# CC13x0 register map
File version: 2.0
CPU: CM3 r2p1, little endian, no MPU, no FPU, 0x3 interrupt priority bits, 0x0 interrupts
Registers are 32-bit, read-write, reset 0x0 unless marked. A register's access mark holds for its fields unless they carry their own. Offsets are from the block's base; [hi:lo] are bit positions; {n}, {i} and the like mark numbered series.

## AON_BATMON — Always On (AON) Battery And Temperature MONitor (BATMON) residing in the AON domain Note: This module only supports 32 bit Read/Write access from MCU.
Base 0x40095000
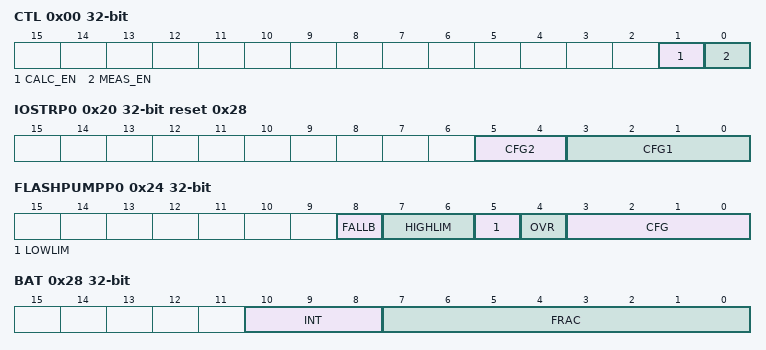
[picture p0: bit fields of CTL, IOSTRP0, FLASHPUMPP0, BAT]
0x00 CTL — Internal. Only to be used through TI provided API.
  [1] CALC_EN, [0] MEAS_EN
0x04 MEASCFG — Internal. Only to be used through TI provided API.
  [1:0] PER
0x0C TEMPP0 — Internal. Only to be used through TI provided API.
  [7:0] CFG
0x10 TEMPP1 — Internal. Only to be used through TI provided API.
  [5:0] CFG
0x14 TEMPP2 — Internal. Only to be used through TI provided API.
  [4:0] CFG
0x18 BATMONP0 — Internal. Only to be used through TI provided API.
  [5:0] CFG
0x1C BATMONP1 — Internal. Only to be used through TI provided API.
  [5:0] CFG
0x20 IOSTRP0 reset 0x28 — Internal. Only to be used through TI provided API.
  [5:4] CFG2, [3:0] CFG1
0x24 FLASHPUMPP0 — Internal. Only to be used through TI provided API.
  [8] FALLB, [7:6] HIGHLIM, [5] LOWLIM, [4] OVR, [3:0] CFG
0x28 BAT ro — Last Measured Battery Voltage This register may be read while BATUPD.STAT = 1
  [10:8] INT, [7:0] FRAC
0x2C BATUPD — Battery Update Indicates BAT Updates
  [0] STAT write-1-clears
0x30 TEMP ro — Temperature Last Measured Temperature in Degrees Celsius This register may be read while TEMPUPD.STAT = 1.
  [16:8] INT
0x34 TEMPUPD — Temperature Update Indicates TEMP Updates
  [0] STAT write-1-clears

## AON_EVENT — This module configures the event fabric located in the AON domain. Note: This module is only supporting 32 bit ReadWrite access from MCU
Base 0x40093000
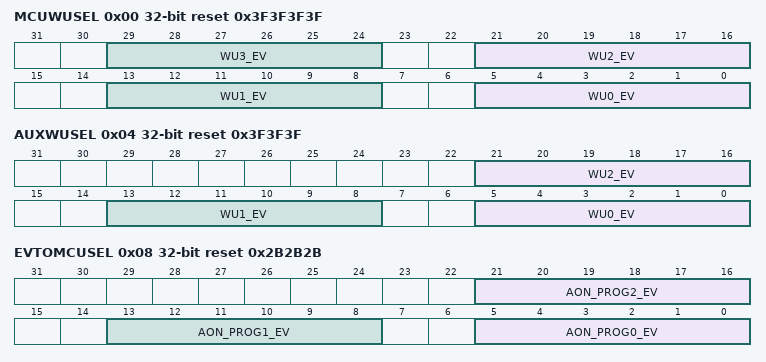
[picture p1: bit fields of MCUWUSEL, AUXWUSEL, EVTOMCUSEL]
0x00 MCUWUSEL reset 0x3F3F3F3F — Wake-up Selector For MCU This register contains pointers to 4 events which are routed to AON_WUC as wakeup sources for MCU. AON_WUC will start a wakeup sequence for the MCU domain when either of the 4 selected events are asserted. A wakeup sequence will guarantee that the MCU power switches are turned on, LDO resources are available and SCLK_HF is available and selected as clock source for MCU. Note: It is recommended ( or required when AON_WUC:MCUCLK.PWR_DWN_SRC=NONE) to also setup a wakeup event here before MCU is requesting powerdown. ( PRCM requests uLDO, see conditions in PRCM:VDCTL.ULDO ) as it will speed up the wakeup procedure.
  [8n+5:8n] WU{n}_EV (n=0..3)
0x04 AUXWUSEL reset 0x3F3F3F — Wake-up Selector For AUX This register contains pointers to 3 events which are routed to AON_WUC as wakeup sources for AUX. AON_WUC will start a wakeup sequence for the AUX domain when either of the 3 selected events are asserted. A wakeup sequence will guarantee that the AUX power switches are turned on, LDO resources are available and SCLK_HF is available and selected as clock source for AUX. Note: It is recommended ( or required when AON_WUC:AUXCLK.PWR_DWN_SRC=NONE) to also setup a wakeup event here before AUX is requesting powerdown. ( AUX_WUC:PWRDWNREQ.REQ is asserted] ) as it will speed up the wakeup procedure.
  [21:16] WU2_EV, [13:8] WU1_EV, [5:0] WU0_EV
0x08 EVTOMCUSEL reset 0x2B2B2B — Event Selector For MCU Event Fabric This register contains pointers for 3 AON events that are routed to the MCU Event Fabric EVENT
  [21:16] AON_PROG2_EV, [13:8] AON_PROG1_EV, [5:0] AON_PROG0_EV
0x0C RTCSEL reset 0x3F — RTC Capture Event Selector For AON_RTC This register contains a pointer to select an AON event for RTC capture. Please refer to AON_RTC:CH1CAPT
  [5:0] RTC_CH1_CAPT_EV

## AON_IOC — Always On (AON) IO Controller - controls IO operation when the MCU IO Controller (IOC) is powered off and resides in the AON domain. Note: This module only supports 32 bit Read/Write access from MCU.
Base 0x40094000
0x00 IOSTRMIN reset 0x3 — Internal. Only to be used through TI provided API.
  [2:0] GRAY_CODE
0x04 IOSTRMED reset 0x6 — Internal. Only to be used through TI provided API.
  [2:0] GRAY_CODE
0x08 IOSTRMAX reset 0x5 — Internal. Only to be used through TI provided API.
  [2:0] GRAY_CODE
0x0C IOCLATCH reset 0x1 — IO Latch Control Controls transparency of all latches holding I/O or configuration state from the MCU IOC
  [0] EN
0x10 CLK32KCTL reset 0x1 — SCLK_LF External Output Control
  [0] OE_N
